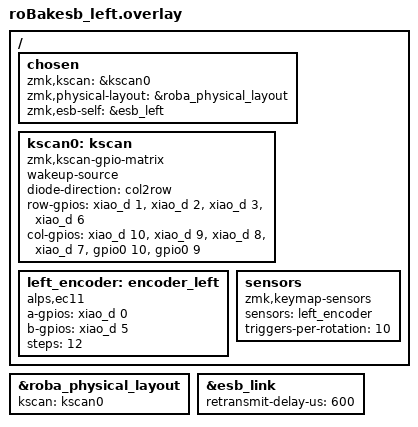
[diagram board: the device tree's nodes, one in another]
#include "roBa_matrix.dtsi"
#include "roBakesb_addr.dtsi"

/ {
    chosen {
        zmk,kscan = &kscan0;
        zmk,physical-layout = &roba_physical_layout;
        zmk,esb-self = &esb_left;
    };

    kscan0: kscan {
        compatible = "zmk,kscan-gpio-matrix";
        wakeup-source;
        diode-direction = "col2row";
        row-gpios
            = <&xiao_d 1 (GPIO_ACTIVE_HIGH | GPIO_PULL_DOWN)>
            , <&xiao_d 2 (GPIO_ACTIVE_HIGH | GPIO_PULL_DOWN)>
            , <&xiao_d 3 (GPIO_ACTIVE_HIGH | GPIO_PULL_DOWN)>
            , <&xiao_d 6 (GPIO_ACTIVE_HIGH | GPIO_PULL_DOWN)>
            ;
        col-gpios
            = <&xiao_d 10 GPIO_ACTIVE_HIGH>
            , <&xiao_d 9 GPIO_ACTIVE_HIGH>
            , <&xiao_d 8 GPIO_ACTIVE_HIGH>
            , <&xiao_d 7 GPIO_ACTIVE_HIGH>
            , <&gpio0 10 GPIO_ACTIVE_HIGH>
            , <&gpio0 9 GPIO_ACTIVE_HIGH>
            ;
    };

    left_encoder: encoder_left {
        compatible = "alps,ec11";
        a-gpios = <&xiao_d 0 (GPIO_ACTIVE_HIGH | GPIO_PULL_UP)>;
        b-gpios = <&xiao_d 5 (GPIO_ACTIVE_HIGH | GPIO_PULL_UP)>;
        steps = <12>;
        status = "okay";
    };

    sensors: sensors {
        compatible = "zmk,keymap-sensors";
        sensors = <&left_encoder>;
        triggers-per-rotation = <10>;
    };
};

&roba_physical_layout {
    kscan = <&kscan0>;
};

&esb_link {
    retransmit-delay-us = <600>;
};
